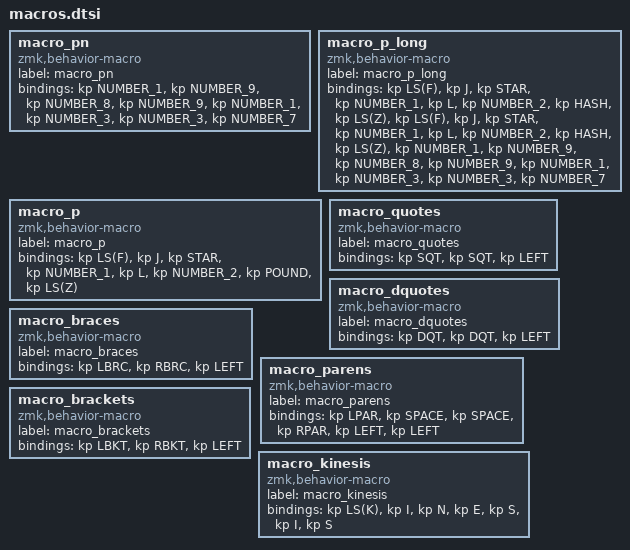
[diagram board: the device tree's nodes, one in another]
macro_pn: macro_pn{
compatible = "zmk,behavior-macro";
label = "macro_pn";
#binding-cells = <0>;
bindings = <&kp NUMBER_1>, <&kp NUMBER_9>, <&kp NUMBER_8>, <&kp NUMBER_9>, <&kp NUMBER_1>, <&kp NUMBER_3>, <&kp NUMBER_3>, <&kp NUMBER_7>;
};
macro_p_long: macro_p_long{
compatible = "zmk,behavior-macro";
label = "macro_p_long";
#binding-cells = <0>;
bindings = <&kp LS(F)>, <&kp J>, <&kp STAR>, <&kp NUMBER_1>, <&kp L>, <&kp NUMBER_2>, <&kp HASH>, <&kp LS(Z)>, <&kp LS(F)>, <&kp J>, <&kp STAR>, <&kp NUMBER_1>, <&kp L>, <&kp NUMBER_2>, <&kp HASH>, <&kp LS(Z)>, <&kp NUMBER_1>, <&kp NUMBER_9>, <&kp NUMBER_8>, <&kp NUMBER_9>, <&kp NUMBER_1>, <&kp NUMBER_3>, <&kp NUMBER_3>, <&kp NUMBER_7>;
};
macro_p: macro_p{
compatible = "zmk,behavior-macro";
label = "macro_p";
#binding-cells = <0>;
bindings = <&kp LS(F)>, <&kp J>, <&kp STAR>, <&kp NUMBER_1>, <&kp L>, <&kp NUMBER_2>, <&kp POUND>, <&kp LS(Z)>;
};
macro_quotes: macro_quotes{
compatible = "zmk,behavior-macro";
label = "macro_quotes";
#binding-cells = <0>;
bindings = <&kp SQT>, <&kp SQT>, <&kp LEFT>;
};
macro_dquotes: macro_dquotes{
compatible = "zmk,behavior-macro";
label = "macro_dquotes";
#binding-cells = <0>;
bindings = <&kp DQT>, <&kp DQT>, <&kp LEFT>;
};
macro_braces: macro_braces{
compatible = "zmk,behavior-macro";
label = "macro_braces";
#binding-cells = <0>;
bindings = <&kp LBRC>, <&kp RBRC>, <&kp LEFT>;
};
macro_parens: macro_parens{
compatible = "zmk,behavior-macro";
label = "macro_parens";
#binding-cells = <0>;
bindings = <&kp LPAR>, <&kp SPACE>, <&kp SPACE>, <&kp RPAR>, <&kp LEFT>, <&kp LEFT>;
};
macro_brackets: macro_brackets{
compatible = "zmk,behavior-macro";
label = "macro_brackets";
#binding-cells = <0>;
bindings = <&kp LBKT>, <&kp RBKT>, <&kp LEFT>;
};
macro_kinesis: macro_kinesis{
compatible = "zmk,behavior-macro";
label = "macro_kinesis";
#binding-cells = <0>;
bindings = <&kp LS(K)>, <&kp I>, <&kp N>, <&kp E>, <&kp S>, <&kp I>, <&kp S>;
};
